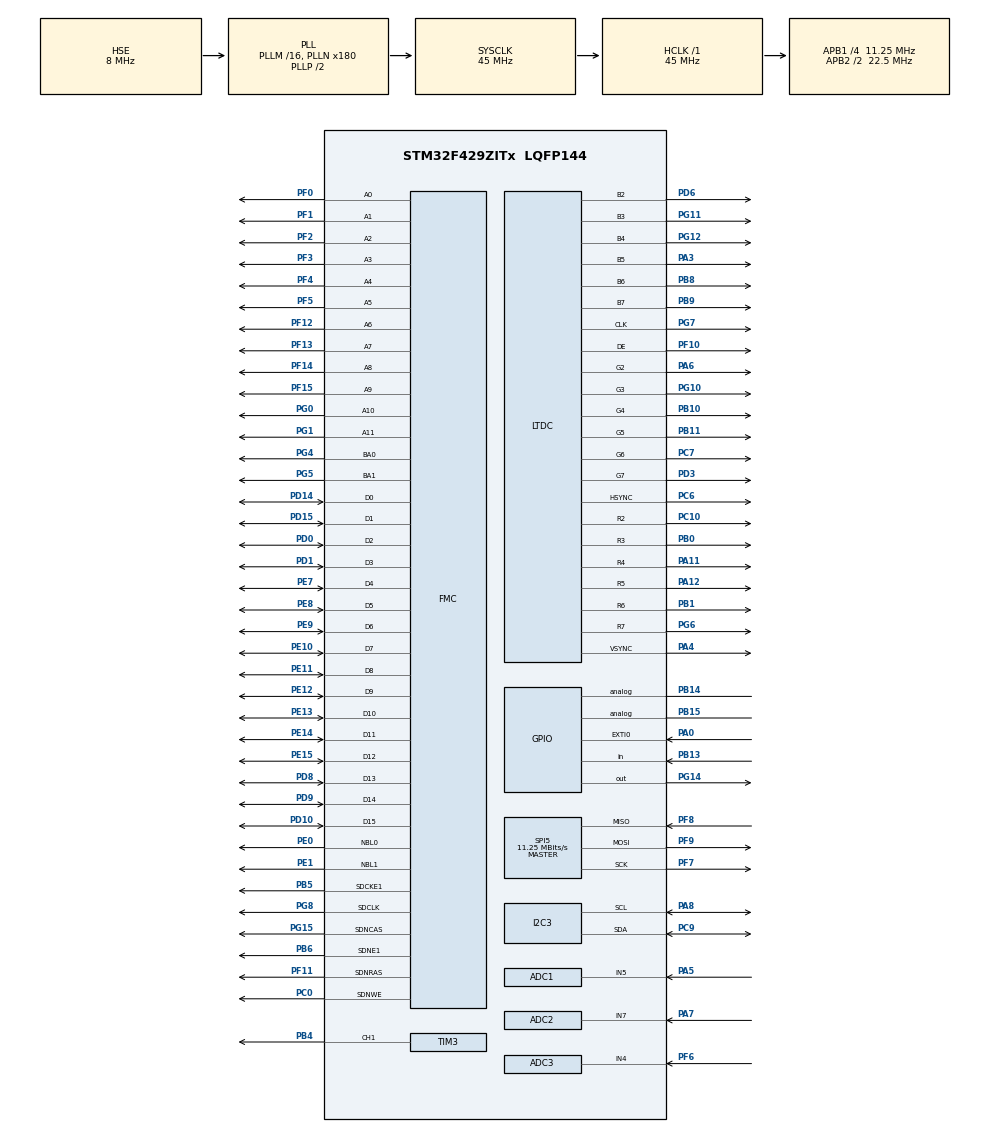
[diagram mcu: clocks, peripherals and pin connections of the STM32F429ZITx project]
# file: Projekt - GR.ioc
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ADC1.Channel-1\#ChannelRegularConversion=ADC_CHANNEL_5
ADC1.NbrOfConversionFlag=1
ADC1.Rank-1\#ChannelRegularConversion=1
ADC1.SamplingTime-1\#ChannelRegularConversion=ADC_SAMPLETIME_3CYCLES
ADC1.master=1
ADC2.Channel-2\#ChannelRegularConversion=ADC_CHANNEL_7
ADC2.NbrOfConversionFlag=1
ADC2.Rank-2\#ChannelRegularConversion=1
ADC2.SamplingTime-2\#ChannelRegularConversion=ADC_SAMPLETIME_3CYCLES
ADC3.Channel-2\#ChannelRegularConversion=ADC_CHANNEL_4
ADC3.NbrOfConversionFlag=1
ADC3.Rank-2\#ChannelRegularConversion=1
ADC3.SamplingTime-2\#ChannelRegularConversion=ADC_SAMPLETIME_3CYCLES
DMA2D.ColorMode=DMA2D_OUTPUT_RGB565
Mcu.Family=STM32F4
Mcu.Name=STM32F429ZITx
Mcu.Package=LQFP144
NVIC.EXTI0_IRQn=true\:0\:0\:false\:false\:true\:true\:true\:true
NVIC.PriorityGroup=NVIC_PRIORITYGROUP_4
NVIC.TIM4_IRQn=true\:0\:0\:false\:false\:true\:true\:true\:true
NVIC.TIM6_DAC_IRQn=true\:0\:0\:false\:false\:true\:true\:true\:true
PA0/WKUP.Signal=GPXTI0
PA11.Mode=RGB666
PA11.Signal=LTDC_R4
PA12.Mode=RGB666
PA12.Signal=LTDC_R5
PA3.Mode=RGB666
PA3.Signal=LTDC_B5
PA4.Mode=RGB666
PA4.Signal=LTDC_VSYNC
PA5.Signal=ADCx_IN5
PA6.Mode=RGB666
PA6.Signal=LTDC_G2
PA7.Signal=ADCx_IN7
PA8.Mode=I2C
PA8.Signal=I2C3_SCL
PB0.Mode=RGB666
PB0.Signal=LTDC_R3
PB1.Mode=RGB666
PB1.Signal=LTDC_R6
PB10.Mode=RGB666
PB10.Signal=LTDC_G4
PB11.Mode=RGB666
PB11.Signal=LTDC_G5
PB13.Signal=GPIO_Input
PB14.Signal=GPIO_Analog
PB15.Signal=GPIO_Analog
PB4.Signal=S_TIM3_CH1
PB5.Mode=SdramChipSelect2_1
PB5.Signal=FMC_SDCKE1
PB6.Mode=SdramChipSelect2_1
PB6.Signal=FMC_SDNE1
PB8.Mode=RGB666
PB8.Signal=LTDC_B6
PB9.Mode=RGB666
PB9.Signal=LTDC_B7
PC0.Signal=FMC_SDNWE
PC10.Mode=RGB666
PC10.Signal=LTDC_R2
PC6.Mode=RGB666
PC6.Signal=LTDC_HSYNC
PC7.Mode=RGB666
PC7.Signal=LTDC_G6
PC9.Mode=I2C
PC9.Signal=I2C3_SDA
PD0.Signal=FMC_D2_DA2
PD1.Signal=FMC_D3_DA3
PD10.Signal=FMC_D15_DA15
PD14.Signal=FMC_D0_DA0
PD15.Signal=FMC_D1_DA1
PD3.Mode=RGB666
PD3.Signal=LTDC_G7
PD6.Mode=RGB666
PD6.Signal=LTDC_B2
PD8.Signal=FMC_D13_DA13
PD9.Signal=FMC_D14_DA14
PE0.Signal=FMC_NBL0
PE1.Signal=FMC_NBL1
PE10.Signal=FMC_D7_DA7
PE11.Signal=FMC_D8_DA8
PE12.Signal=FMC_D9_DA9
PE13.Signal=FMC_D10_DA10
PE14.Signal=FMC_D11_DA11
PE15.Signal=FMC_D12_DA12
PE7.Signal=FMC_D4_DA4
PE8.Signal=FMC_D5_DA5
PE9.Signal=FMC_D6_DA6
PF0.Signal=FMC_A0
PF1.Signal=FMC_A1
PF10.Mode=RGB666
PF10.Signal=LTDC_DE
PF11.Signal=FMC_SDNRAS
PF12.Signal=FMC_A6
PF13.Signal=FMC_A7
PF14.Signal=FMC_A8
PF15.Signal=FMC_A9
PF2.Signal=FMC_A2
PF3.Signal=FMC_A3
PF4.Signal=FMC_A4
PF5.Signal=FMC_A5
PF6.Mode=IN4
PF6.Signal=ADC3_IN4
PF7.Mode=Full_Duplex_Master
PF7.Signal=SPI5_SCK
PF8.Mode=Full_Duplex_Master
PF8.Signal=SPI5_MISO
PF9.Mode=Full_Duplex_Master
PF9.Signal=SPI5_MOSI
PG0.Signal=FMC_A10
PG1.Signal=FMC_A11
PG10.Mode=RGB666
PG10.Signal=LTDC_G3
PG11.Mode=RGB666
PG11.Signal=LTDC_B3
PG12.Mode=RGB666
PG12.Signal=LTDC_B4
PG14.Signal=GPIO_Output
PG15.Signal=FMC_SDNCAS
PG4.Signal=FMC_A14_BA0
PG5.Signal=FMC_A15_BA1
PG6.Mode=RGB666
PG6.Signal=LTDC_R7
PG7.Mode=RGB666
PG7.Signal=LTDC_CLK
PG8.Signal=FMC_SDCLK
PH0/OSC_IN.Mode=HSE-External-Oscillator
PH0/OSC_IN.Signal=RCC_OSC_IN
PH1/OSC_OUT.Mode=HSE-External-Oscillator
PH1/OSC_OUT.Signal=RCC_OSC_OUT
ProjectManager.HeapSize=0x200
ProjectManager.StackSize=0x400
ProjectManager.TargetToolchain=STM32CubeIDE
RCC.48MHZClocksFreq_Value=22500000
RCC.AHBFreq_Value=45000000
RCC.APB1CLKDivider=RCC_HCLK_DIV4
RCC.APB1Freq_Value=11250000
RCC.APB1TimFreq_Value=22500000
RCC.APB2CLKDivider=RCC_HCLK_DIV2
RCC.APB2Freq_Value=22500000
RCC.APB2TimFreq_Value=45000000
RCC.CortexFreq_Value=45000000
RCC.HCLKFreq_Value=45000000
RCC.HSE_VALUE=8000000
RCC.HSI_VALUE=16000000
RCC.LSE_VALUE=32768
RCC.PLLN=180
RCC.PLLSAIR=2
RCC.PLLSourceVirtual=RCC_PLLSOURCE_HSE
RCC.SYSCLKFreq_VALUE=45000000
RCC.SYSCLKSource=RCC_SYSCLKSOURCE_PLLCLK
RCC.VCOOutputFreq_Value=90000000
SH.ADCx_IN5.0=ADC1_IN5,IN5
SH.ADCx_IN7.0=ADC2_IN7,IN7
SH.FMC_A0.0=FMC_A0,12b-sda1
SH.FMC_A1.0=FMC_A1,12b-sda1
SH.FMC_A10.0=FMC_A10,12b-sda1
SH.FMC_A11.0=FMC_A11,12b-sda1
SH.FMC_A14_BA0.0=FMC_BA0,FourSdramBanks1
SH.FMC_A15_BA1.0=FMC_BA1,FourSdramBanks1
SH.FMC_A2.0=FMC_A2,12b-sda1
SH.FMC_A3.0=FMC_A3,12b-sda1
SH.FMC_A4.0=FMC_A4,12b-sda1
SH.FMC_A5.0=FMC_A5,12b-sda1
SH.FMC_A6.0=FMC_A6,12b-sda1
SH.FMC_A7.0=FMC_A7,12b-sda1
SH.FMC_A8.0=FMC_A8,12b-sda1
SH.FMC_A9.0=FMC_A9,12b-sda1
SH.FMC_D0_DA0.0=FMC_D0,sd-16b-d1
SH.FMC_D10_DA10.0=FMC_D10,sd-16b-d1
SH.FMC_D11_DA11.0=FMC_D11,sd-16b-d1
SH.FMC_D12_DA12.0=FMC_D12,sd-16b-d1
SH.FMC_D13_DA13.0=FMC_D13,sd-16b-d1
SH.FMC_D14_DA14.0=FMC_D14,sd-16b-d1
SH.FMC_D15_DA15.0=FMC_D15,sd-16b-d1
SH.FMC_D1_DA1.0=FMC_D1,sd-16b-d1
SH.FMC_D2_DA2.0=FMC_D2,sd-16b-d1
SH.FMC_D3_DA3.0=FMC_D3,sd-16b-d1
SH.FMC_D4_DA4.0=FMC_D4,sd-16b-d1
SH.FMC_D5_DA5.0=FMC_D5,sd-16b-d1
SH.FMC_D6_DA6.0=FMC_D6,sd-16b-d1
SH.FMC_D7_DA7.0=FMC_D7,sd-16b-d1
SH.FMC_D8_DA8.0=FMC_D8,sd-16b-d1
SH.FMC_D9_DA9.0=FMC_D9,sd-16b-d1
SH.FMC_NBL0.0=FMC_NBL0,Sd2ByteEnable1
SH.FMC_NBL1.0=FMC_NBL1,Sd2ByteEnable1
SH.FMC_SDCLK.0=FMC_SDCLK,12b-sda1
SH.FMC_SDNCAS.0=FMC_SDNCAS,12b-sda1
SH.FMC_SDNRAS.0=FMC_SDNRAS,12b-sda1
SH.FMC_SDNWE.0=FMC_SDNWE,12b-sda1
SH.S_TIM3_CH1.0=TIM3_CH1,PWM Generation1 CH1
SPI5.BaudRatePrescaler=SPI_BAUDRATEPRESCALER_2
SPI5.CalculateBaudRate=11.25 MBits/s
SPI5.Direction=SPI_DIRECTION_2LINES
SPI5.Mode=SPI_MODE_MASTER
SPI5.VirtualType=VM_MASTER
TIM3.Channel-PWM\ Generation1\ CH1=TIM_CHANNEL_1
TIM3.Period=999
TIM3.Prescaler=79
TIM3.Pulse-PWM\ Generation1\ CH1=499
TIM4.Period=0
TIM4.Prescaler=15
TIM6.Period=3
TIM6.Prescaler=0
TIM6.TIM_MasterOutputTrigger=TIM_TRGO_UPDATE
VP_DMA2D_VS_DMA2D.Mode=DMA2D_Activate
VP_TIM4_VS_ClockSourceINT.Mode=Internal
VP_TIM6_VS_ClockSourceINT.Mode=Enable_Timer
board=custom

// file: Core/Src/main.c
/* USER CODE BEGIN Header */
/**
  ******************************************************************************
  * @file           : main.c
  * @brief          : Main program body
  ******************************************************************************
  * @attention
  *
  * Copyright (c) 2024 STMicroelectronics.
  * All rights reserved.
  *
  * This software is licensed under terms that can be found in the LICENSE file
  * in the root directory of this software component.
  * If no LICENSE file comes with this software, it is provided AS-IS.
  *
  ******************************************************************************
  */
/* USER CODE END Header */
#include "main.h"

/* USER CODE BEGIN Includes */
#include "stm32f429i_discovery_lcd.h"
/* USER CODE END Includes */

ADC_HandleTypeDef hadc1;
ADC_HandleTypeDef hadc2;
ADC_HandleTypeDef hadc3;

DMA2D_HandleTypeDef hdma2d;

I2C_HandleTypeDef hi2c3;

LTDC_HandleTypeDef hltdc;

SPI_HandleTypeDef hspi5;

TIM_HandleTypeDef htim3;
TIM_HandleTypeDef htim4;
TIM_HandleTypeDef htim6;

SDRAM_HandleTypeDef hsdram1;

void SystemClock_Config(void);
static void MX_GPIO_Init(void);
static void MX_ADC2_Init(void);
static void MX_TIM6_Init(void);
static void MX_TIM4_Init(void);
static void MX_FMC_Init(void);
static void MX_LTDC_Init(void);
static void MX_DMA2D_Init(void);
static void MX_I2C3_Init(void);
static void MX_SPI5_Init(void);
static void MX_ADC1_Init(void);
static void MX_ADC3_Init(void);
static void MX_TIM3_Init(void);

/* USER CODE BEGIN 0 */
struct Note {
	int freq;
	float dur;
};

struct Song {
	struct Note notes[1000];
	int length;
};

int Action(int *option, int *valuex, int *valuey, int *valueButton, int maxoption, int *freq_index, int *len_index) {
	if (*valuey == -1 && *option < 3 && *valuex==0) {
		*option += 1;
	}
	if (*valuey == 1 && *option > 0 && *valuex == 0) {
		*option -= 1;
	}
	if (*valuey == 0 && *option == 0 && *valuex == 1 && *freq_index<24) {
		*freq_index += 1;
	}
	if (*valuey == 0 && *option == 0 && *valuex == -1 && *freq_index>0) {
		*freq_index -= 1;
	}
	if (*valuey == 0 && *option == 1 && *valuex == 1 && *len_index < 4) {
		*len_index += 1;
	}
	if (*valuey == 0 && *option == 1 && *valuex == -1 && *len_index > 0) {
		*len_index -= 1;
	}
	if (*valuey == 0 && *option == 3 && *valuex == 0 && *valueButton == 1) {
		return 0;
	}
	if (*valuey == 0 && *option == 0 && *valuex == 0 && *valueButton == 1) {
		return 2;
	}
	if (*option > maxoption) {
		*option = maxoption;
	}
	return 1;
}

void Display(int mode, int* option, int* freq, float* dur) {
	if (mode == 0) {
		BSP_LCD_DisplayStringAtLine(0, (uint8_t*)"                     ");
		BSP_LCD_DisplayStringAtLine(0, (uint8_t*)"Playing a Song");
		BSP_LCD_DisplayStringAtLine(1, (uint8_t*)"                     ");
		BSP_LCD_SetTextColor(LCD_COLOR_RED);
		BSP_LCD_DisplayStringAtLine(1, (uint8_t*)"Record a Song");
		BSP_LCD_SetTextColor(LCD_COLOR_WHITE);
		BSP_LCD_DisplayStringAtLine(2, (uint8_t*)"                     ");
		BSP_LCD_DisplayStringAtLine(3, (uint8_t*)"                     ");
		BSP_LCD_DisplayStringAtLine(4, (uint8_t*)"                     ");
	}
	if (mode == 1) {
		BSP_LCD_SetTextColor(LCD_COLOR_WHITE);
		BSP_LCD_DisplayStringAtLine(0, (uint8_t*)"                  ");
		BSP_LCD_DisplayStringAtLine(0, (uint8_t*)"Recording song");
		BSP_LCD_DisplayStringAtLine(1, (uint8_t*)"                  ");
		if (*option == 0) {
			BSP_LCD_SetTextColor(LCD_COLOR_RED);
		}
		if (*freq == 308) {
			BSP_LCD_DisplayStringAtLine(1, (uint8_t*)"Pitch: C1");
		}
		if (*freq == 290) {
			BSP_LCD_DisplayStringAtLine(1, (uint8_t*)"Pitch: CIS1");
		}
		if (*freq == 274) {
			BSP_LCD_DisplayStringAtLine(1, (uint8_t*)"Pitch: D1");
		}
		if (*freq == 256) {
			BSP_LCD_DisplayStringAtLine(1, (uint8_t*)"Pitch: DIS1");
		}
		if (*freq == 244) {
			BSP_LCD_DisplayStringAtLine(1, (uint8_t*)"Pitch: E1");
		}
		if (*freq == 230) {
			BSP_LCD_DisplayStringAtLine(1, (uint8_t*)"Pitch: F1");
		}
		if (*freq == 217) {
			BSP_LCD_DisplayStringAtLine(1, (uint8_t*)"Pitch: FIS1");
		}
		if (*freq == 204) {
			BSP_LCD_DisplayStringAtLine(1, (uint8_t*)"Pitch: G1");
		}
		if (*freq == 192) {
			BSP_LCD_DisplayStringAtLine(1, (uint8_t*)"Pitch: GIS1");
		}
		if (*freq == 182) {
			BSP_LCD_DisplayStringAtLine(1, (uint8_t*)"Pitch: A1");
		}
		if (*freq == 171) {
			BSP_LCD_DisplayStringAtLine(1, (uint8_t*)"Pitch: AIS1");
		}
		if (*freq == 163) {
			BSP_LCD_DisplayStringAtLine(1, (uint8_t*)"Pitch: B1");
		}
		if (*freq == 153) {
			BSP_LCD_DisplayStringAtLine(1, (uint8_t*)"Pitch: C2");
		}
		if (*freq == 144) {
			BSP_LCD_DisplayStringAtLine(1, (uint8_t*)"Pitch: CIS2");
		}
		if (*freq == 136) {
			BSP_LCD_DisplayStringAtLine(1, (uint8_t*)"Pitch: D2");
		}
		if (*freq == 128) {
			BSP_LCD_DisplayStringAtLine(1, (uint8_t*)"Pitch: DIS2");
		}
		if (*freq == 121) {
			BSP_LCD_DisplayStringAtLine(1, (uint8_t*)"Pitch: E2");
		}
		if (*freq == 114) {
			BSP_LCD_DisplayStringAtLine(1, (uint8_t*)"Pitch: F2");
		}
		if (*freq == 108) {
			BSP_LCD_DisplayStringAtLine(1, (uint8_t*)"Pitch: FIS2");
		}
		if (*freq == 102) {
			BSP_LCD_DisplayStringAtLine(1, (uint8_t*)"Pitch: G2");
		}
		if (*freq == 96) {
			BSP_LCD_DisplayStringAtLine(1, (uint8_t*)"Pitch: GIS2");
		}
		if (*freq == 91) {
			BSP_LCD_DisplayStringAtLine(1, (uint8_t*)"Pitch: A2");
		}
		if (*freq == 86) {
			BSP_LCD_DisplayStringAtLine(1, (uint8_t*)"Pitch: AIS2");
		}
		if (*freq == 81) {
			BSP_LCD_DisplayStringAtLine(1, (uint8_t*)"Pitch: B2");
		}
		if (*freq == 0) {
					BSP_LCD_DisplayStringAtLine(1, (uint8_t*)"Pitch: Pause");
		}
		BSP_LCD_SetTextColor(LCD_COLOR_WHITE);
		BSP_LCD_DisplayStringAtLine(2, (uint8_t*)"                         ");
		if (*option == 1) {
			BSP_LCD_SetTextColor(LCD_COLOR_RED);
		}
		if (*dur == (float)1.0) {
			BSP_LCD_DisplayStringAtLine(2, (uint8_t*)("Length: Full"));
		}
		if (*dur == (float)0.5) {
			BSP_LCD_DisplayStringAtLine(2, (uint8_t*)("Length: Half"));
		}
		if (*dur == (float)0.25) {
			BSP_LCD_DisplayStringAtLine(2, (uint8_t*)("Length: Quarter"));
		}
		if (*dur == (float)0.125) {
			BSP_LCD_DisplayStringAtLine(2, (uint8_t*)("Length: Eighth"));
		}
		if (*dur == (float)0.0625) {
			BSP_LCD_DisplayStringAtLine(2, (uint8_t*)("Length: Sixteenth"));
		}
		BSP_LCD_SetTextColor(LCD_COLOR_WHITE);
		BSP_LCD_DisplayStringAtLine(3, (uint8_t*)"                     ");
		if (*option == 2) {
			BSP_LCD_SetTextColor(LCD_COLOR_RED);
		}
		BSP_LCD_DisplayStringAtLine(3, (uint8_t*)"Confirm");
		BSP_LCD_SetTextColor(LCD_COLOR_WHITE);
		BSP_LCD_DisplayStringAtLine(4, (uint8_t*)"                     ");
		if (*option == 3) {
			BSP_LCD_SetTextColor(LCD_COLOR_RED);
		}
		BSP_LCD_DisplayStringAtLine(4, (uint8_t*)"Finish");
		BSP_LCD_SetTextColor(LCD_COLOR_WHITE);
	}
	if (mode == 2) {
		BSP_LCD_DisplayStringAtLine(0, (uint8_t*)"                     ");
		BSP_LCD_DisplayStringAtLine(0, (uint8_t*)"Song paused");
		BSP_LCD_DisplayStringAtLine(1, (uint8_t*)"                     ");
		BSP_LCD_SetTextColor(LCD_COLOR_RED);
		BSP_LCD_DisplayStringAtLine(1, (uint8_t*)"Register a Song");
		BSP_LCD_SetTextColor(LCD_COLOR_WHITE);
		BSP_LCD_DisplayStringAtLine(2, (uint8_t*)"                     ");
		BSP_LCD_DisplayStringAtLine(3, (uint8_t*)"                     ");
		BSP_LCD_DisplayStringAtLine(4, (uint8_t*)"                     ");
	}
}

struct Song registerSong(int *option, int *valuex, int *valuey, int *valueButton){
	struct Song nowa;
	int tmp = 0;
	nowa.length=0;
	int freq_index = 0;
	int len_index = 0;
	int freq_table[] = { 308, 290, 274, 256, 244, 230, 217, 204, 192, 182, 171, 163, 153, 144, 136, 128, 121, 114, 108, 102, 96, 91, 86, 81, 0};
	float len_table[] = { 1.0,0.5,0.25,0.125,0.0625 };
	Display(1, option, &freq_table[freq_index], &len_table[len_index]);
	while (Action(option, valuex, valuey, valueButton,3, &freq_index, &len_index) > 0 || nowa.length==0) {
		if (tmp==1) Display(1, option, &freq_table[freq_index], &len_table[len_index]);
		if (*valueButton == 1 && *option == 2) {
			nowa.notes[nowa.length].freq = freq_table[freq_index];
			nowa.notes[nowa.length].dur = len_table[len_index];
			nowa.length += 1;
		}
		HAL_ADC_Start(&hadc1);
		HAL_ADC_Start(&hadc2);
		HAL_ADC_Start(&hadc3);
		HAL_Delay(20);
		if (readAnalogStickx(HAL_ADC_GetValue(&hadc1), valuex) || readAnalogSticky(HAL_ADC_GetValue(&hadc2), valuey) || readButton(valueButton)) tmp = 1;
		else tmp = 0;
	}
	*option=0;
	return nowa;
}

void playNote(struct Note note, float basespeed) {
	HAL_Delay(100);
	HAL_TIM_PWM_Stop(&htim3, TIM_CHANNEL_1);
	if (note.freq!=0) HAL_TIM_PWM_Start(&htim3, TIM_CHANNEL_1);
	TIM3->ARR = note.freq;
	TIM3->CCR1 = TIM3->ARR * 0.5;
	HAL_Delay((int)1000*basespeed * note.dur);
}

int readAnalogStickx(uint32_t value, int* val) {
	int new_val;
	if (value > 3200) {
		new_val = 1;
	}
	else if (value < 3000) {
		new_val = -1;
	}
	else new_val = 0;
	if (*val!=new_val){
		*val=new_val;
		return 1;
	}
	return 0;
}

int readAnalogSticky(uint32_t value, int* val) {
	int new_val;
	if (value > 3400) {
		new_val = -1;
	}
	else if (value < 2800) {
		new_val = 1;
	}
	else new_val = 0;
	if (*val!=new_val){
		*val=new_val;
		return 1;
	}
	return 0;
}

int readButton(int *val) {
	int new_val;
	if (HAL_GPIO_ReadPin(GPIOB, GPIO_PIN_13) == GPIO_PIN_SET) {
		new_val = 1;
	}
	else if (HAL_GPIO_ReadPin(GPIOB, GPIO_PIN_13) == GPIO_PIN_RESET) {
		new_val = 0;
	}
	if (*val != new_val) {
		*val = new_val;
		return 1;
	}
	return 0;
}

int readPotentiometer(int *val) {
	uint32_t value = HAL_ADC_GetValue(&hadc3);
	int new_val;
	if (value > 3200) {
		new_val = 2;
	}
	else if (value < 3200 && value > 700) {
		new_val = 1;
	}
	else if (value < 700) {
		new_val = 0;
	}
	if (*val != new_val) {
		*val = new_val;
		return 1;
	}
	return 0;
}

void playSong(struct Song song, float speed) {
	float basespeed;
	if (speed == 0) {
		basespeed = 0.5;
	}
	if (speed == 1) {
		basespeed = 1.0;
	}
	if (speed == 2) {
		basespeed = 2.0;
	}
	for (int i = 0; i < song.length; i++) {
		playNote(song.notes[i], basespeed);
	}
}

/* USER CODE END 0 */

int main(void)
{

  /* MCU Configuration--------------------------------------------------------*/

  /* Reset of all peripherals, Initializes the Flash interface and the Systick. */
  HAL_Init();

  /* Configure the system clock */
  SystemClock_Config();

  /* Initialize all configured peripherals */
  MX_GPIO_Init();
  MX_ADC2_Init();
  MX_TIM6_Init();
  MX_TIM4_Init();
  MX_FMC_Init();
  MX_LTDC_Init();
  MX_DMA2D_Init();
  MX_I2C3_Init();
  MX_SPI5_Init();
  MX_ADC1_Init();
  MX_ADC3_Init();
  MX_TIM3_Init();

  /* Infinite loop */
  /* USER CODE BEGIN WHILE */
  int on=0; // Zmienna przechowująca stan przycisku włączania
  // Glosnik: PB4
  int valuex; // PA5
  int valuey; // PA7
  int option=0;
  int potval=0; // PF6
  int valueButton = 0; // PB13
  int phvi =0;
  float phvf =0;
  struct Song song;
  int x = 25;

  BSP_LCD_Init();
  BSP_LCD_LayerDefaultInit(LCD_BACKGROUND_LAYER, LCD_FRAME_BUFFER);
  BSP_LCD_Clear(LCD_COLOR_BLACK);
  BSP_LCD_SetBackColor(LCD_COLOR_BLACK);
  BSP_LCD_SetTextColor(LCD_COLOR_WHITE);
  Display(0, &option,&phvi,&phvf);
  BSP_LCD_DisplayStringAtLine(0, (uint8_t*)"                  ");
  BSP_LCD_DisplayStringAtLine(0, (uint8_t*)"No song recorded");

  HAL_TIM_PWM_Start(&htim3, TIM_CHANNEL_1); //wartosc zegara prc: 79 counter_period: 999 pulse: 499
  while (1)
  {
	 if (HAL_GPIO_ReadPin(GPIOG,  GPIO_PIN_14)==GPIO_PIN_SET) {
		 if (on) {
			 on = 0;
			 Display(2, &option,0,0);
		 }
		 else {
			 on = 1;
			 Display(0, &option,0,0);
		 }
		 HAL_GPIO_WritePin(GPIOG, GPIO_PIN_14, GPIO_PIN_RESET);
	 }
	 if (on) {
		 HAL_TIM_PWM_Start(&htim3, TIM_CHANNEL_1);
		 playSong(song, potval);
	 }
	 else {
		 HAL_TIM_PWM_Stop(&htim3, TIM_CHANNEL_1);
	 }
	 HAL_ADC_Start(&hadc1);
	 HAL_ADC_Start(&hadc2);
	 HAL_ADC_Start(&hadc3);
	 readAnalogStickx(HAL_ADC_GetValue(&hadc1), &valuex);
	 readAnalogSticky(HAL_ADC_GetValue(&hadc2), &valuey);
	 readButton(&valueButton);
	 if (Action(&option, &valuex, &valuey, &valueButton, 0,0,0) == 2) {
		 song = registerSong(&option, &valuex, &valuey, &valueButton);
		 on = 1;
		 Display(0, &option,0,0);
	 }
	 readPotentiometer(&potval);
    /* USER CODE END WHILE */

  }
}

void SystemClock_Config(void)
{
  RCC_OscInitTypeDef RCC_OscInitStruct = {0};
  RCC_ClkInitTypeDef RCC_ClkInitStruct = {0};

  /** Configure the main internal regulator output voltage
  */
  __HAL_RCC_PWR_CLK_ENABLE();
  __HAL_PWR_VOLTAGESCALING_CONFIG(PWR_REGULATOR_VOLTAGE_SCALE3);

  /** Initializes the RCC Oscillators according to the specified parameters
  * in the RCC_OscInitTypeDef structure.
  */
  RCC_OscInitStruct.OscillatorType = RCC_OSCILLATORTYPE_HSE;
  RCC_OscInitStruct.HSEState = RCC_HSE_ON;
  RCC_OscInitStruct.PLL.PLLState = RCC_PLL_ON;
  RCC_OscInitStruct.PLL.PLLSource = RCC_PLLSOURCE_HSE;
  RCC_OscInitStruct.PLL.PLLM = 16;
  RCC_OscInitStruct.PLL.PLLN = 180;
  RCC_OscInitStruct.PLL.PLLP = RCC_PLLP_DIV2;
  RCC_OscInitStruct.PLL.PLLQ = 4;
  if (HAL_RCC_OscConfig(&RCC_OscInitStruct) != HAL_OK)
  {
    Error_Handler();
  }

  /** Initializes the CPU, AHB and APB buses clocks
  */
  RCC_ClkInitStruct.ClockType = RCC_CLOCKTYPE_HCLK|RCC_CLOCKTYPE_SYSCLK
                              |RCC_CLOCKTYPE_PCLK1|RCC_CLOCKTYPE_PCLK2;
  RCC_ClkInitStruct.SYSCLKSource = RCC_SYSCLKSOURCE_PLLCLK;
  RCC_ClkInitStruct.AHBCLKDivider = RCC_SYSCLK_DIV1;
  RCC_ClkInitStruct.APB1CLKDivider = RCC_HCLK_DIV4;
  RCC_ClkInitStruct.APB2CLKDivider = RCC_HCLK_DIV2;

  if (HAL_RCC_ClockConfig(&RCC_ClkInitStruct, FLASH_LATENCY_1) != HAL_OK)
  {
    Error_Handler();
  }
}

static void MX_ADC1_Init(void)
{

  ADC_ChannelConfTypeDef sConfig = {0};

  /** Configure the global features of the ADC (Clock, Resolution, Data Alignment and number of conversion)
  */
  hadc1.Instance = ADC1;
  hadc1.Init.ClockPrescaler = ADC_CLOCK_SYNC_PCLK_DIV2;
  hadc1.Init.Resolution = ADC_RESOLUTION_12B;
  hadc1.Init.ScanConvMode = DISABLE;
  hadc1.Init.ContinuousConvMode = DISABLE;
  hadc1.Init.DiscontinuousConvMode = DISABLE;
  hadc1.Init.ExternalTrigConvEdge = ADC_EXTERNALTRIGCONVEDGE_NONE;
  hadc1.Init.ExternalTrigConv = ADC_SOFTWARE_START;
  hadc1.Init.DataAlign = ADC_DATAALIGN_RIGHT;
  hadc1.Init.NbrOfConversion = 1;
  hadc1.Init.DMAContinuousRequests = DISABLE;
  hadc1.Init.EOCSelection = ADC_EOC_SINGLE_CONV;
  if (HAL_ADC_Init(&hadc1) != HAL_OK)
  {
    Error_Handler();
  }

  /** Configure for the selected ADC regular channel its corresponding rank in the sequencer and its sample time.
  */
  sConfig.Channel = ADC_CHANNEL_5;
  sConfig.Rank = 1;
  sConfig.SamplingTime = ADC_SAMPLETIME_3CYCLES;
  if (HAL_ADC_ConfigChannel(&hadc1, &sConfig) != HAL_OK)
  {
    Error_Handler();
  }

}

static void MX_ADC2_Init(void)
{

  ADC_ChannelConfTypeDef sConfig = {0};

  /** Configure the global features of the ADC (Clock, Resolution, Data Alignment and number of conversion)
  */
  hadc2.Instance = ADC2;
  hadc2.Init.ClockPrescaler = ADC_CLOCK_SYNC_PCLK_DIV2;
  hadc2.Init.Resolution = ADC_RESOLUTION_12B;
  hadc2.Init.ScanConvMode = DISABLE;
  hadc2.Init.ContinuousConvMode = DISABLE;
  hadc2.Init.DiscontinuousConvMode = DISABLE;
  hadc2.Init.ExternalTrigConvEdge = ADC_EXTERNALTRIGCONVEDGE_NONE;
  hadc2.Init.ExternalTrigConv = ADC_SOFTWARE_START;
  hadc2.Init.DataAlign = ADC_DATAALIGN_RIGHT;
  hadc2.Init.NbrOfConversion = 1;
  hadc2.Init.DMAContinuousRequests = DISABLE;
  hadc2.Init.EOCSelection = ADC_EOC_SINGLE_CONV;
  if (HAL_ADC_Init(&hadc2) != HAL_OK)
  {
    Error_Handler();
  }

  /** Configure for the selected ADC regular channel its corresponding rank in the sequencer and its sample time.
  */
  sConfig.Channel = ADC_CHANNEL_7;
  sConfig.Rank = 1;
  sConfig.SamplingTime = ADC_SAMPLETIME_3CYCLES;
  if (HAL_ADC_ConfigChannel(&hadc2, &sConfig) != HAL_OK)
  {
    Error_Handler();
  }

}

static void MX_ADC3_Init(void)
{

  ADC_ChannelConfTypeDef sConfig = {0};

  /** Configure the global features of the ADC (Clock, Resolution, Data Alignment and number of conversion)
  */
  hadc3.Instance = ADC3;
  hadc3.Init.ClockPrescaler = ADC_CLOCK_SYNC_PCLK_DIV2;
  hadc3.Init.Resolution = ADC_RESOLUTION_12B;
  hadc3.Init.ScanConvMode = DISABLE;
  hadc3.Init.ContinuousConvMode = DISABLE;
  hadc3.Init.DiscontinuousConvMode = DISABLE;
  hadc3.Init.ExternalTrigConvEdge = ADC_EXTERNALTRIGCONVEDGE_NONE;
  hadc3.Init.ExternalTrigConv = ADC_SOFTWARE_START;
  hadc3.Init.DataAlign = ADC_DATAALIGN_RIGHT;
  hadc3.Init.NbrOfConversion = 1;
  hadc3.Init.DMAContinuousRequests = DISABLE;
  hadc3.Init.EOCSelection = ADC_EOC_SINGLE_CONV;
  if (HAL_ADC_Init(&hadc3) != HAL_OK)
  {
    Error_Handler();
  }

  /** Configure for the selected ADC regular channel its corresponding rank in the sequencer and its sample time.
  */
  sConfig.Channel = ADC_CHANNEL_4;
  sConfig.Rank = 1;
  sConfig.SamplingTime = ADC_SAMPLETIME_3CYCLES;
  if (HAL_ADC_ConfigChannel(&hadc3, &sConfig) != HAL_OK)
  {
    Error_Handler();
  }

}

static void MX_DMA2D_Init(void)
{

  hdma2d.Instance = DMA2D;
  hdma2d.Init.Mode = DMA2D_M2M;
  hdma2d.Init.ColorMode = DMA2D_OUTPUT_RGB565;
  hdma2d.Init.OutputOffset = 0;
  hdma2d.LayerCfg[1].InputOffset = 0;
  hdma2d.LayerCfg[1].InputColorMode = DMA2D_INPUT_RGB565;
  hdma2d.LayerCfg[1].AlphaMode = DMA2D_NO_MODIF_ALPHA;
  hdma2d.LayerCfg[1].InputAlpha = 0;
  if (HAL_DMA2D_Init(&hdma2d) != HAL_OK)
  {
    Error_Handler();
  }
  if (HAL_DMA2D_ConfigLayer(&hdma2d, 1) != HAL_OK)
  {
    Error_Handler();
  }

}

static void MX_I2C3_Init(void)
{

  hi2c3.Instance = I2C3;
  hi2c3.Init.ClockSpeed = 100000;
  hi2c3.Init.DutyCycle = I2C_DUTYCYCLE_2;
  hi2c3.Init.OwnAddress1 = 0;
  hi2c3.Init.AddressingMode = I2C_ADDRESSINGMODE_7BIT;
  hi2c3.Init.DualAddressMode = I2C_DUALADDRESS_DISABLE;
  hi2c3.Init.OwnAddress2 = 0;
  hi2c3.Init.GeneralCallMode = I2C_GENERALCALL_DISABLE;
  hi2c3.Init.NoStretchMode = I2C_NOSTRETCH_DISABLE;
  if (HAL_I2C_Init(&hi2c3) != HAL_OK)
  {
    Error_Handler();
  }

  /** Configure Analogue filter
  */
  if (HAL_I2CEx_ConfigAnalogFilter(&hi2c3, I2C_ANALOGFILTER_ENABLE) != HAL_OK)
  {
    Error_Handler();
  }

  /** Configure Digital filter
  */
  if (HAL_I2CEx_ConfigDigitalFilter(&hi2c3, 0) != HAL_OK)
  {
    Error_Handler();
  }

}

static void MX_LTDC_Init(void)
{

  LTDC_LayerCfgTypeDef pLayerCfg = {0};
  LTDC_LayerCfgTypeDef pLayerCfg1 = {0};

  hltdc.Instance = LTDC;
  hltdc.Init.HSPolarity = LTDC_HSPOLARITY_AL;
  hltdc.Init.VSPolarity = LTDC_VSPOLARITY_AL;
  hltdc.Init.DEPolarity = LTDC_DEPOLARITY_AL;
  hltdc.Init.PCPolarity = LTDC_PCPOLARITY_IPC;
  hltdc.Init.HorizontalSync = 7;
  hltdc.Init.VerticalSync = 3;
  hltdc.Init.AccumulatedHBP = 14;
  hltdc.Init.AccumulatedVBP = 5;
  hltdc.Init.AccumulatedActiveW = 654;
  hltdc.Init.AccumulatedActiveH = 485;
  hltdc.Init.TotalWidth = 660;
  hltdc.Init.TotalHeigh = 487;
  hltdc.Init.Backcolor.Blue = 0;
  hltdc.Init.Backcolor.Green = 0;
  hltdc.Init.Backcolor.Red = 0;
  if (HAL_LTDC_Init(&hltdc) != HAL_OK)
  {
    Error_Handler();
  }
  pLayerCfg.WindowX0 = 0;
  pLayerCfg.WindowX1 = 0;
  pLayerCfg.WindowY0 = 0;
  pLayerCfg.WindowY1 = 0;
  pLayerCfg.PixelFormat = LTDC_PIXEL_FORMAT_ARGB8888;
  pLayerCfg.Alpha = 0;
  pLayerCfg.Alpha0 = 0;
  pLayerCfg.BlendingFactor1 = LTDC_BLENDING_FACTOR1_CA;
  pLayerCfg.BlendingFactor2 = LTDC_BLENDING_FACTOR2_CA;
  pLayerCfg.FBStartAdress = 0;
  pLayerCfg.ImageWidth = 0;
  pLayerCfg.ImageHeight = 0;
  pLayerCfg.Backcolor.Blue = 0;
  pLayerCfg.Backcolor.Green = 0;
  pLayerCfg.Backcolor.Red = 0;
  if (HAL_LTDC_ConfigLayer(&hltdc, &pLayerCfg, 0) != HAL_OK)
  {
    Error_Handler();
  }
  pLayerCfg1.WindowX0 = 0;
  pLayerCfg1.WindowX1 = 0;
  pLayerCfg1.WindowY0 = 0;
  pLayerCfg1.WindowY1 = 0;
  pLayerCfg1.PixelFormat = LTDC_PIXEL_FORMAT_ARGB8888;
  pLayerCfg1.Alpha = 0;
  pLayerCfg1.Alpha0 = 0;
  pLayerCfg1.BlendingFactor1 = LTDC_BLENDING_FACTOR1_CA;
  pLayerCfg1.BlendingFactor2 = LTDC_BLENDING_FACTOR2_CA;
  pLayerCfg1.FBStartAdress = 0;
  pLayerCfg1.ImageWidth = 0;
  pLayerCfg1.ImageHeight = 0;
  pLayerCfg1.Backcolor.Blue = 0;
  pLayerCfg1.Backcolor.Green = 0;
  pLayerCfg1.Backcolor.Red = 0;
  if (HAL_LTDC_ConfigLayer(&hltdc, &pLayerCfg1, 1) != HAL_OK)
  {
    Error_Handler();
  }

}

static void MX_SPI5_Init(void)
{

  /* SPI5 parameter configuration*/
  hspi5.Instance = SPI5;
  hspi5.Init.Mode = SPI_MODE_MASTER;
  hspi5.Init.Direction = SPI_DIRECTION_2LINES;
  hspi5.Init.DataSize = SPI_DATASIZE_8BIT;
  hspi5.Init.CLKPolarity = SPI_POLARITY_LOW;
  hspi5.Init.CLKPhase = SPI_PHASE_1EDGE;
  hspi5.Init.NSS = SPI_NSS_SOFT;
  hspi5.Init.BaudRatePrescaler = SPI_BAUDRATEPRESCALER_2;
  hspi5.Init.FirstBit = SPI_FIRSTBIT_MSB;
  hspi5.Init.TIMode = SPI_TIMODE_DISABLE;
  hspi5.Init.CRCCalculation = SPI_CRCCALCULATION_DISABLE;
  hspi5.Init.CRCPolynomial = 10;
  if (HAL_SPI_Init(&hspi5) != HAL_OK)
  {
    Error_Handler();
  }

}

static void MX_TIM3_Init(void)
{

  TIM_MasterConfigTypeDef sMasterConfig = {0};
  TIM_OC_InitTypeDef sConfigOC = {0};

  htim3.Instance = TIM3;
  htim3.Init.Prescaler = 79;
  htim3.Init.CounterMode = TIM_COUNTERMODE_UP;
  htim3.Init.Period = 999;
  htim3.Init.ClockDivision = TIM_CLOCKDIVISION_DIV1;
  htim3.Init.AutoReloadPreload = TIM_AUTORELOAD_PRELOAD_DISABLE;
  if (HAL_TIM_PWM_Init(&htim3) != HAL_OK)
  {
    Error_Handler();
  }
  sMasterConfig.MasterOutputTrigger = TIM_TRGO_RESET;
  sMasterConfig.MasterSlaveMode = TIM_MASTERSLAVEMODE_DISABLE;
  if (HAL_TIMEx_MasterConfigSynchronization(&htim3, &sMasterConfig) != HAL_OK)
  {
    Error_Handler();
  }
  sConfigOC.OCMode = TIM_OCMODE_PWM1;
  sConfigOC.Pulse = 499;
  sConfigOC.OCPolarity = TIM_OCPOLARITY_HIGH;
  sConfigOC.OCFastMode = TIM_OCFAST_DISABLE;
  if (HAL_TIM_PWM_ConfigChannel(&htim3, &sConfigOC, TIM_CHANNEL_1) != HAL_OK)
  {
    Error_Handler();
  }
  HAL_TIM_MspPostInit(&htim3);

}

static void MX_TIM4_Init(void)
{

  TIM_ClockConfigTypeDef sClockSourceConfig = {0};
  TIM_MasterConfigTypeDef sMasterConfig = {0};

  htim4.Instance = TIM4;
  htim4.Init.Prescaler = 15;
  htim4.Init.CounterMode = TIM_COUNTERMODE_UP;
  htim4.Init.Period = 0;
  htim4.Init.ClockDivision = TIM_CLOCKDIVISION_DIV1;
  htim4.Init.AutoReloadPreload = TIM_AUTORELOAD_PRELOAD_DISABLE;
  if (HAL_TIM_Base_Init(&htim4) != HAL_OK)
  {
    Error_Handler();
  }
  sClockSourceConfig.ClockSource = TIM_CLOCKSOURCE_INTERNAL;
  if (HAL_TIM_ConfigClockSource(&htim4, &sClockSourceConfig) != HAL_OK)
  {
    Error_Handler();
  }
  sMasterConfig.MasterOutputTrigger = TIM_TRGO_RESET;
  sMasterConfig.MasterSlaveMode = TIM_MASTERSLAVEMODE_DISABLE;
  if (HAL_TIMEx_MasterConfigSynchronization(&htim4, &sMasterConfig) != HAL_OK)
  {
    Error_Handler();
  }

}

static void MX_TIM6_Init(void)
{

  TIM_MasterConfigTypeDef sMasterConfig = {0};

  htim6.Instance = TIM6;
  htim6.Init.Prescaler = 0;
  htim6.Init.CounterMode = TIM_COUNTERMODE_UP;
  htim6.Init.Period = 3;
  htim6.Init.AutoReloadPreload = TIM_AUTORELOAD_PRELOAD_DISABLE;
  if (HAL_TIM_Base_Init(&htim6) != HAL_OK)
  {
    Error_Handler();
  }
  sMasterConfig.MasterOutputTrigger = TIM_TRGO_UPDATE;
  sMasterConfig.MasterSlaveMode = TIM_MASTERSLAVEMODE_DISABLE;
  if (HAL_TIMEx_MasterConfigSynchronization(&htim6, &sMasterConfig) != HAL_OK)
  {
    Error_Handler();
  }

}

/* FMC initialization function */
static void MX_FMC_Init(void)
{

  FMC_SDRAM_TimingTypeDef SdramTiming = {0};

  /** Perform the SDRAM1 memory initialization sequence
  */
  hsdram1.Instance = FMC_SDRAM_DEVICE;
  /* hsdram1.Init */
  hsdram1.Init.SDBank = FMC_SDRAM_BANK2;
  hsdram1.Init.ColumnBitsNumber = FMC_SDRAM_COLUMN_BITS_NUM_8;
  hsdram1.Init.RowBitsNumber = FMC_SDRAM_ROW_BITS_NUM_12;
  hsdram1.Init.MemoryDataWidth = FMC_SDRAM_MEM_BUS_WIDTH_16;
  hsdram1.Init.InternalBankNumber = FMC_SDRAM_INTERN_BANKS_NUM_4;
  hsdram1.Init.CASLatency = FMC_SDRAM_CAS_LATENCY_1;
  hsdram1.Init.WriteProtection = FMC_SDRAM_WRITE_PROTECTION_DISABLE;
  hsdram1.Init.SDClockPeriod = FMC_SDRAM_CLOCK_DISABLE;
  hsdram1.Init.ReadBurst = FMC_SDRAM_RBURST_DISABLE;
  hsdram1.Init.ReadPipeDelay = FMC_SDRAM_RPIPE_DELAY_0;
  /* SdramTiming */
  SdramTiming.LoadToActiveDelay = 16;
  SdramTiming.ExitSelfRefreshDelay = 16;
  SdramTiming.SelfRefreshTime = 16;
  SdramTiming.RowCycleDelay = 16;
  SdramTiming.WriteRecoveryTime = 16;
  SdramTiming.RPDelay = 16;
  SdramTiming.RCDDelay = 16;

  if (HAL_SDRAM_Init(&hsdram1, &SdramTiming) != HAL_OK)
  {
    Error_Handler( );
  }

}

static void MX_GPIO_Init(void)
{
  GPIO_InitTypeDef GPIO_InitStruct = {0};

  /* GPIO Ports Clock Enable */
  __HAL_RCC_GPIOF_CLK_ENABLE();
  __HAL_RCC_GPIOH_CLK_ENABLE();
  __HAL_RCC_GPIOC_CLK_ENABLE();
  __HAL_RCC_GPIOA_CLK_ENABLE();
  __HAL_RCC_GPIOB_CLK_ENABLE();
  __HAL_RCC_GPIOG_CLK_ENABLE();
  __HAL_RCC_GPIOE_CLK_ENABLE();
  __HAL_RCC_GPIOD_CLK_ENABLE();

  /*Configure GPIO pin Output Level */
  HAL_GPIO_WritePin(GPIOG, GPIO_PIN_14, GPIO_PIN_RESET);

  /*Configure GPIO pin : PA0 */
  GPIO_InitStruct.Pin = GPIO_PIN_0;
  GPIO_InitStruct.Mode = GPIO_MODE_IT_RISING;
  GPIO_InitStruct.Pull = GPIO_NOPULL;
  HAL_GPIO_Init(GPIOA, &GPIO_InitStruct);

  /*Configure GPIO pin : PB13 */
  GPIO_InitStruct.Pin = GPIO_PIN_13;
  GPIO_InitStruct.Mode = GPIO_MODE_INPUT;
  GPIO_InitStruct.Pull = GPIO_NOPULL;
  HAL_GPIO_Init(GPIOB, &GPIO_InitStruct);

  /*Configure GPIO pins : PB14 PB15 */
  GPIO_InitStruct.Pin = GPIO_PIN_14|GPIO_PIN_15;
  GPIO_InitStruct.Mode = GPIO_MODE_ANALOG;
  GPIO_InitStruct.Pull = GPIO_NOPULL;
  HAL_GPIO_Init(GPIOB, &GPIO_InitStruct);

  /*Configure GPIO pin : PG14 */
  GPIO_InitStruct.Pin = GPIO_PIN_14;
  GPIO_InitStruct.Mode = GPIO_MODE_OUTPUT_PP;
  GPIO_InitStruct.Pull = GPIO_NOPULL;
  GPIO_InitStruct.Speed = GPIO_SPEED_FREQ_LOW;
  HAL_GPIO_Init(GPIOG, &GPIO_InitStruct);

  /* EXTI interrupt init*/
  HAL_NVIC_SetPriority(EXTI0_IRQn, 0, 0);
  HAL_NVIC_EnableIRQ(EXTI0_IRQn);

}

void Error_Handler(void)
{
  __disable_irq();
  while (1)
  {
  }
}
